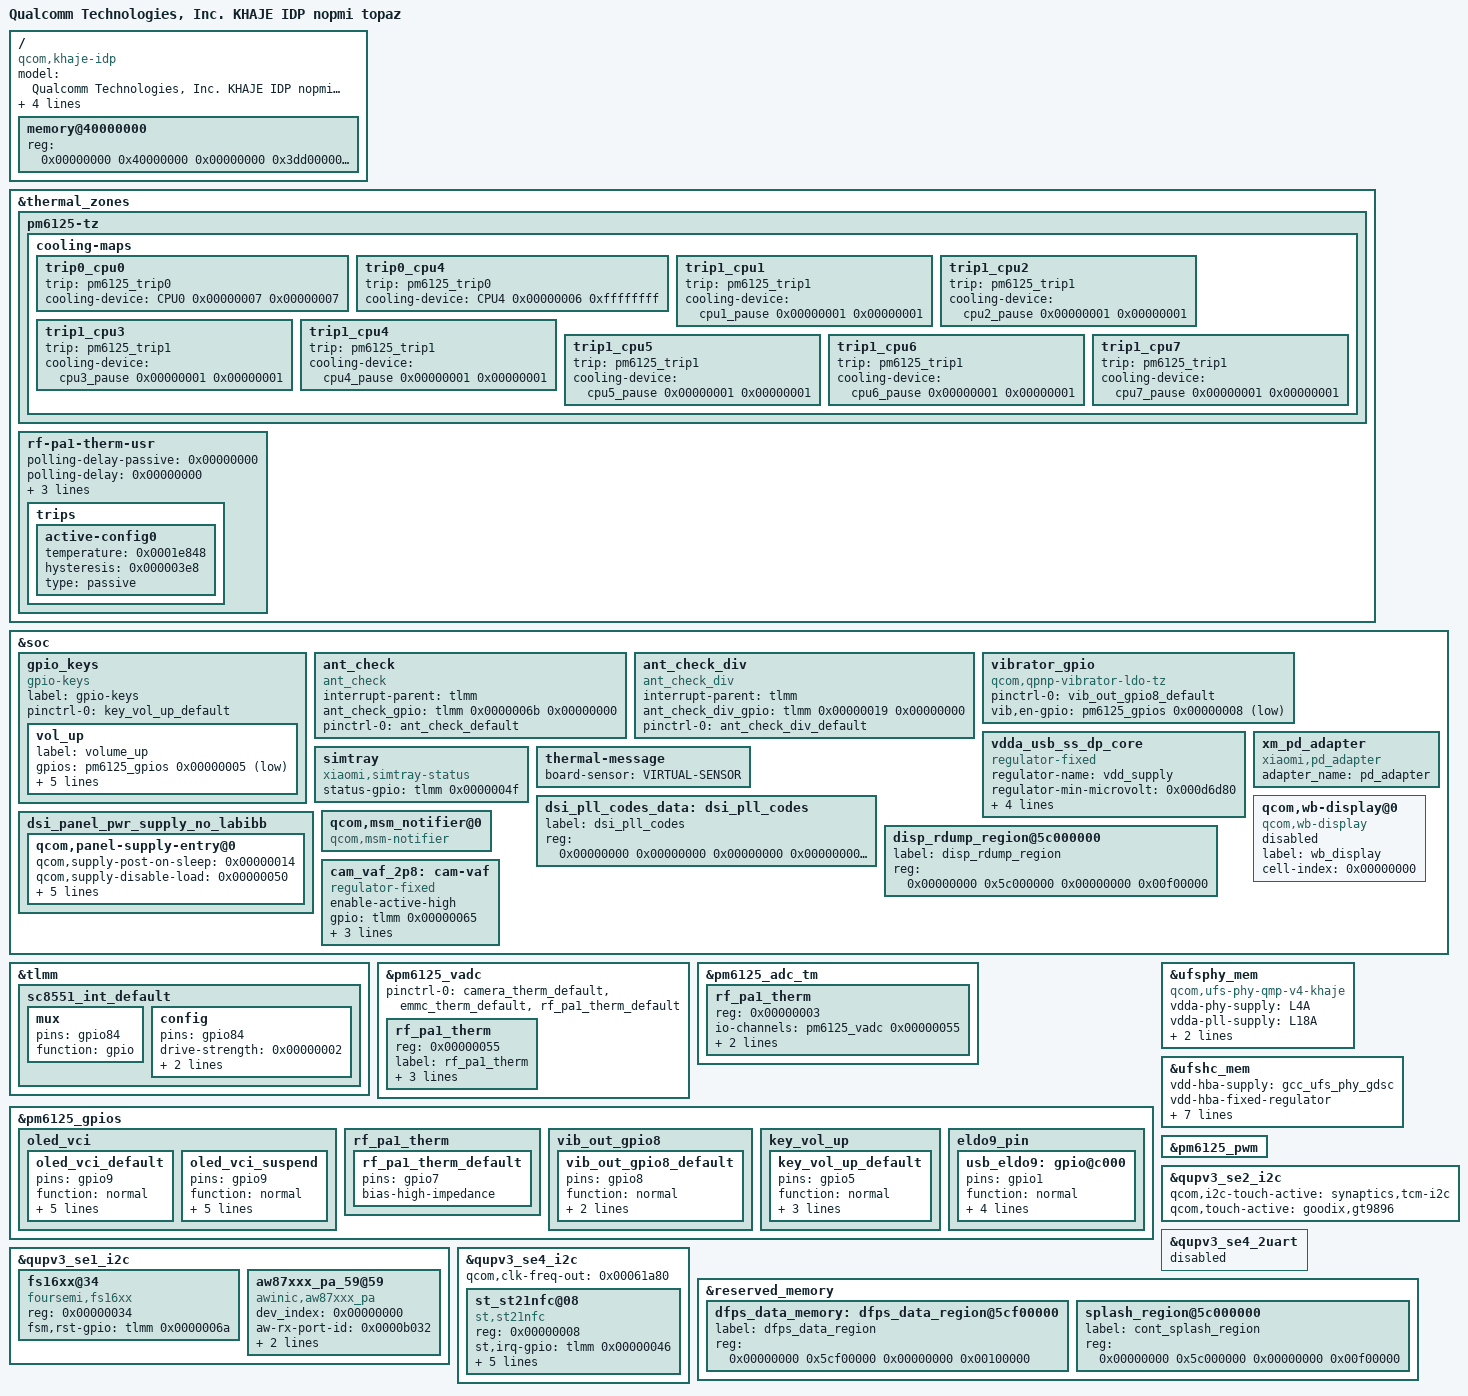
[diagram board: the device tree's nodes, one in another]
/dts-v1/;

/*
 * DT da placa topaz (Redmi Note 12 4G), gerada por tools/curate_dt.py.
 * Fontes: topaz-overlay.dtso (sha256 d2cc07730af939f1...) e
 * topaz-live-reference.dts (memory). Nao revisado por upstream.
 * Nao flashar. A memoria e preenchida pelo bootloader.
 */

#include "khaje.dtsi"

/ {
	model = "Qualcomm Technologies, Inc. KHAJE IDP nopmi topaz";
	compatible = "qcom,khaje-idp", "qcom,khaje", "qcom,idp";
	qcom,msm-id = <0x00000206 0x00010000>;
	qcom,board-id = <0x00030022 0x00000000>;
	qcom,pmic-id = <0x0000002d 0x00000000 0x00000000 0x00000000>;
};

/ {
	memory@40000000 {
		device_type = "memory";
		reg = <0x00000000 0x40000000 0x00000000 0x3dd00000 0x00000000 0xc0000000 0x00000000 0x80000000 0x00000000 0x80000000 0x00000000 0x40000000>;
	};
};

&thermal_zones {
	pm6125-tz {
		cooling-maps {
			trip0_cpu0 {
				trip = <&pm6125_trip0>;
				cooling-device = <&CPU0 0x00000007 0x00000007>;
			};
			trip0_cpu4 {
				trip = <&pm6125_trip0>;
				cooling-device = <&CPU4 0x00000006 0xffffffff>;
			};
			trip1_cpu1 {
				trip = <&pm6125_trip1>;
				cooling-device = <&cpu1_pause 0x00000001 0x00000001>;
			};
			trip1_cpu2 {
				trip = <&pm6125_trip1>;
				cooling-device = <&cpu2_pause 0x00000001 0x00000001>;
			};
			trip1_cpu3 {
				trip = <&pm6125_trip1>;
				cooling-device = <&cpu3_pause 0x00000001 0x00000001>;
			};
			trip1_cpu4 {
				trip = <&pm6125_trip1>;
				cooling-device = <&cpu4_pause 0x00000001 0x00000001>;
			};
			trip1_cpu5 {
				trip = <&pm6125_trip1>;
				cooling-device = <&cpu5_pause 0x00000001 0x00000001>;
			};
			trip1_cpu6 {
				trip = <&pm6125_trip1>;
				cooling-device = <&cpu6_pause 0x00000001 0x00000001>;
			};
			trip1_cpu7 {
				trip = <&pm6125_trip1>;
				cooling-device = <&cpu7_pause 0x00000001 0x00000001>;
			};
		};
	};
};

&soc {
};

&tlmm {
};

&pm6125_vadc {
	pinctrl-0 = <&camera_therm_default &emmc_therm_default &rf_pa1_therm_default>;
	rf_pa1_therm {
		reg = <0x00000055>;
		label = "rf_pa1_therm";
		qcom,ratiometric;
		qcom,hw-settle-time = <0x000000c8>;
		qcom,pre-scaling = <0x00000001 0x00000001>;
	};
};

&pm6125_adc_tm {
	status = "okay";
	rf_pa1_therm {
		reg = <0x00000003>;
		io-channels = <&pm6125_vadc 0x00000055>;
		qcom,ratiometric;
		qcom,hw-settle-time-us = <0x000000c8>;
	};
};

&thermal_zones {
	rf-pa1-therm-usr {
		polling-delay-passive = <0x00000000>;
		polling-delay = <0x00000000>;
		thermal-governor = "user_space";
		thermal-sensors = <&pm6125_adc_tm 0x00000003>;
		wake-capable-sensor;
		trips {
			active-config0 {
				temperature = <0x0001e848>;
				hysteresis = <0x000003e8>;
				type = "passive";
			};
		};
	};
};

&pm6125_gpios {
	oled_vci {
		oled_vci_default {
			pins = "gpio9";
			function = "normal";
			input-disable;
			power-source = <0x00000000>;
			bias-disable;
			output-high;
			qcom,drive-strength = <0x00000002>;
		};
		oled_vci_suspend {
			pins = "gpio9";
			function = "normal";
			input-disable;
			power-source = <0x00000000>;
			bias-disable;
			output-low;
			qcom,drive-strength = <0x00000002>;
		};
	};
	rf_pa1_therm {
		rf_pa1_therm_default: rf_pa1_therm_default {
			pins = "gpio7";
			bias-high-impedance;
		};
	};
	vib_out_gpio8 {
		vib_out_gpio8_default: vib_out_gpio8_default {
			pins = "gpio8";
			function = "normal";
			bias-pull-up;
			power-source = <0x00000000>;
		};
	};
	key_vol_up {
		key_vol_up_default: key_vol_up_default {
			pins = "gpio5";
			function = "normal";
			input-enable;
			bias-pull-up;
			power-source = <0x00000000>;
		};
	};
	eldo9_pin {
		usb_eldo9: gpio@c000 {
			pins = "gpio1";
			function = "normal";
			qcom,drive-strength = <0x00000002>;
			power-source = <0x00000000>;
			bias-disable;
			output-high;
		};
	};
};

&soc {
	gpio_keys {
		compatible = "gpio-keys";
		label = "gpio-keys";
		pinctrl-names = "default";
		pinctrl-0 = <&key_vol_up_default>;
		vol_up {
			label = "volume_up";
			gpios = <&pm6125_gpios 0x00000005 0x00000001>;
			linux,input-type = <0x00000001>;
			linux,code = <0x00000073>;
			linux,can-disable;
			debounce-interval = <0x0000000f>;
			gpio-key,wakeup;
		};
	};
	ant_check {
		compatible = "ant_check";
		interrupt-parent = <&tlmm>;
		ant_check_gpio = <&tlmm 0x0000006b 0x00000000>;
		pinctrl-names = "default";
		pinctrl-0 = <&ant_check_default>;
	};
	ant_check_div {
		compatible = "ant_check_div";
		interrupt-parent = <&tlmm>;
		ant_check_div_gpio = <&tlmm 0x00000019 0x00000000>;
		pinctrl-names = "default";
		pinctrl-0 = <&ant_check_div_default>;
	};
	vibrator_gpio {
		status = "okay";
		compatible = "qcom,qpnp-vibrator-ldo-tz";
		pinctrl-names = "default";
		pinctrl-0 = <&vib_out_gpio8_default>;
		vib,en-gpio = <&pm6125_gpios 0x00000008 0x00000001>;
	};
	vdda_usb_ss_dp_core: vdda_usb_ss_dp_core {
		compatible = "regulator-fixed";
		regulator-name = "vdd_supply";
		regulator-min-microvolt = <0x000d6d80>;
		regulator-max-microvolt = <0x000d6d80>;
		enable-active-high;
		gpio = <&pm6125_gpios 0x00000001 0x00000000>;
		pinctrl-names = "default";
		pinctrl-0 = <&usb_eldo9>;
	};
};

&ufsphy_mem {
	compatible = "qcom,ufs-phy-qmp-v4-khaje";
	vdda-phy-supply = <&L4A>;
	vdda-pll-supply = <&L18A>;
	vdda-phy-max-microamp = <0x00014ec4>;
	vdda-pll-max-microamp = <0x0000477c>;
	status = "okay";
};

&ufshc_mem {
	vdd-hba-supply = <&gcc_ufs_phy_gdsc>;
	vdd-hba-fixed-regulator;
	vcc-supply = <&L24A>;
	vcc-max-microamp = <0x000c3500>;
	vccq2-supply = <&L11A>;
	vccq2-max-microamp = <0x000c3500>;
	qcom,vddp-ref-clk-supply = <&L18A>;
	qcom,vddp-ref-clk-max-microamp = <0x00000064>;
	reset-gpios = <&tlmm 0x00000071 0x00000001>;
	reset-names = "rst";
	status = "okay";
};

&pm6125_pwm {
	status = "okay";
};

&qupv3_se2_i2c {
	status = "okay";
	qcom,i2c-touch-active = "synaptics,tcm-i2c";
};

&qupv3_se2_i2c {
};

&tlmm {
};

&qupv3_se1_i2c {
};

&soc {
	xm_pd_adapter {
		compatible = "xiaomi,pd_adapter";
		adapter_name = "pd_adapter";
	};
};

&tlmm {
};

&qupv3_se1_i2c {
	status = "okay";
	#address-cells = <0x00000001>;
	#size-cells = <0x00000000>;
};

&tlmm {
	sc8551_int_default {
		mux {
			pins = "gpio84";
			function = "gpio";
		};
		config {
			pins = "gpio84";
			drive-strength = <0x00000002>;
			bias-pull-up;
			input-enable;
		};
	};
};

&qupv3_se1_i2c {
	status = "okay";
	#address-cells = <0x00000001>;
	#size-cells = <0x00000000>;
};

&soc {
};

&tlmm {
};

&soc {
};

&soc {
	simtray {
		compatible = "xiaomi,simtray-status";
		status-gpio = <&tlmm 0x0000004f 0x00000000>;
	};
	thermal-message {
		board-sensor = "VIRTUAL-SENSOR";
	};
};

&qupv3_se4_2uart {
	status = "disabled";
};

&qupv3_se4_i2c {
	status = "okay";
	qcom,clk-freq-out = <0x00061a80>;
	#address-cells = <0x00000001>;
	#size-cells = <0x00000000>;
	st_st21nfc@08 {
		compatible = "st,st21nfc";
		reg = <0x00000008>;
		st,irq-gpio = <&tlmm 0x00000046 0x00000000>;
		st,reset-gpio = <&tlmm 0x00000045 0x00000000>;
		st,clkreq-gpio = <&tlmm 0x00000047 0x00000000>;
		interrupt-parent = <&tlmm>;
		interrupts = <0x00000046 0x00000000>;
		interrupt-names = "nfc_irq";
		clock-names = "nfc_ref_clk";
		st,clk_pinctrl;
	};
};

&soc {
	dsi_pll_codes_data: dsi_pll_codes {
		label = "dsi_pll_codes";
		reg = <0x00000000 0x00000000 0x00000000 0x00000000 0x00000000 0x00000000 0x00000000 0x00000000 0x00000000 0x00000000 0x00000000 0x00000000 0x00000000 0x00000000 0x00000000 0x00000000 0x00000000 0x00000000 0x00000000 0x00000000 0x00000000 0x00000000 0x00000000 0x00000000 0x00000000 0x00000000 0x00000000 0x00000000 0x00000000 0x00000000 0x00000000 0x00000000 0x00000000 0x00000000 0x00000000 0x00000000 0x00000000 0x00000000 0x00000000 0x00000000 0x00000000 0x00000000 0x00000000 0x00000000 0x00000000 0x00000000 0x00000000 0x00000000 0x00000000 0x00000000 0x00000000 0x00000000 0x00000000 0x00000000 0x00000000 0x00000000 0x00000000 0x00000000 0x00000000 0x00000000 0x00000000 0x00000000 0x00000000 0x00000000 0x00000000 0x00000000 0x00000000 0x00000000 0x00000000 0x00000000 0x00000000 0x00000000 0x00000000 0x00000000 0x00000000 0x00000000 0x00000000 0x00000000 0x00000000 0x00000000 0x00000000 0x00000000 0x00000000 0x00000000 0x00000000 0x00000000 0x00000000 0x00000000 0x00000000 0x00000000 0x00000000 0x00000000 0x00000000 0x00000000 0x00000000 0x00000000 0x00000000 0x00000000 0x00000000 0x00000000 0x00000000 0x00000000 0x00000000 0x00000000 0x00000000 0x00000000 0x00000000 0x00000000 0x00000000 0x00000000 0x00000000 0x00000000 0x00000000 0x00000000 0x00000000 0x00000000 0x00000000 0x00000000 0x00000000 0x00000000 0x00000000 0x00000000 0x00000000 0x00000000 0x00000000 0x00000000 0x00000000 0x00000000>;
	};
};

&soc {
};

&reserved_memory {
	dfps_data_memory: dfps_data_region@5cf00000 {
		label = "dfps_data_region";
		reg = <0x00000000 0x5cf00000 0x00000000 0x00100000>;
	};
};

&soc {
	dsi_panel_pwr_supply_no_labibb: dsi_panel_pwr_supply_no_labibb {
		#size-cells = <0x00000000>;
		#address-cells = <0x00000001>;
		qcom,panel-supply-entry@0 {
			qcom,supply-post-on-sleep = <0x00000014>;
			qcom,supply-disable-load = <0x00000050>;
			qcom,supply-enable-load = <0x0000f230>;
			qcom,supply-max-voltage = <0x001b7740>;
			qcom,supply-min-voltage = <0x001b7740>;
			qcom,supply-name = "vddio";
			reg = <0x00000000>;
		};
	};
	qcom,wb-display@0 {
		label = "wb_display";
		cell-index = <0x00000000>;
		compatible = "qcom,wb-display";
		status = "disabled";
	};
	qcom,msm_notifier@0 {
		compatible = "qcom,msm-notifier";
	};
};

&soc {
	thermal-message {
		board-sensor = "VIRTUAL-SENSOR";
	};
};

&soc {
	disp_rdump_region@5c000000 {
		label = "disp_rdump_region";
		reg = <0x00000000 0x5c000000 0x00000000 0x00f00000>;
	};
};

&reserved_memory {
	splash_region@5c000000 {
		label = "cont_splash_region";
		reg = <0x00000000 0x5c000000 0x00000000 0x00f00000>;
	};
};

&soc {
};

&qupv3_se2_i2c {
	qcom,touch-active = "goodix,gt9896";
	qcom,i2c-touch-active = "focaltech,fts";
	status = "okay";
};

&qupv3_se2_i2c {
	qcom,i2c-touch-active = "synaptics,tcm-i2c";
	status = "okay";
};

&qupv3_se2_i2c {
};

&qupv3_se1_i2c {
	fs16xx@34 {
		reg = <0x00000034>;
		fsm,rst-gpio = <&tlmm 0x0000006a 0x00000000>;
		compatible = "foursemi,fs16xx";
		status = "okay";
	};
	aw87xxx_pa_59@59 {
		status = "okay";
		dev_index = <0x00000000>;
		aw-rx-port-id = <0x0000b032>;
		reset-gpio = <&tlmm 0x0000006a 0x00000000>;
		reg = <0x00000059>;
		compatible = "awinic,aw87xxx_pa";
	};
};

&soc {
};

&soc {
	cam_vaf_2p8: cam-vaf {
		status = "okay";
		enable-active-high;
		gpio = <&tlmm 0x00000065 0x00000000>;
		regulator-max-microvolt = <0x002ab980>;
		regulator-min-microvolt = <0x002ab980>;
		regulator-name = "cam_vaf_2p8";
		compatible = "regulator-fixed";
	};
};

&qupv3_se1_i2c {
	status = "okay";
};
